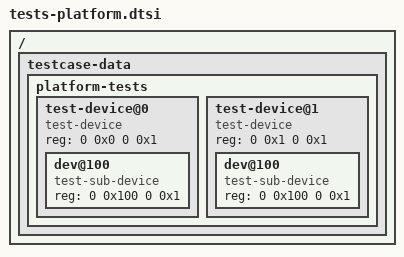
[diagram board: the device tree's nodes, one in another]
// SPDX-License-Identifier: GPL-2.0

/ {
	testcase-data {
		platform-tests {
			#address-cells = <1>;
			#size-cells = <0>;

			test-device@0 {
				compatible = "test-device";
				reg = <0 0x0 0 0x1>;

				#address-cells = <1>;
				#size-cells = <0>;

				dev@100 {
					compatible = "test-sub-device";
					reg = <0 0x100 0 0x1>;
				};
			};

			test-device@1 {
				compatible = "test-device";
				reg = <0 0x1 0 0x1>;

				#address-cells = <1>;
				#size-cells = <0>;

				dev@100 {
					compatible = "test-sub-device",
						     "test-compat2",
						     "test-compat3";
					reg = <0 0x100 0 0x1>;
				};
			};
		};
	};
};
